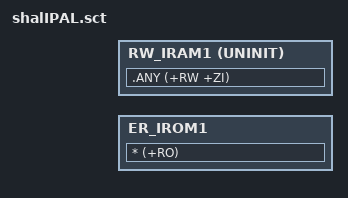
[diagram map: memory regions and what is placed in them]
#! armcc -E
#include "D:\##inhere\sdl\embedded\arm\embody\body\embenv\envcom\eEmemorymap.h"
; due to a bug in linker, you need to put the whole path ... thus change it by hand

; flash starts from SHALIPAL_ROMADDR and its size is SHALIPAL_ROMSIZE
LR_IROM1 EENV_MEMMAP_SHALIPAL_ROMADDR EENV_MEMMAP_SHALIPAL_ROMSIZE  {    ; load region size_region
  ER_IROM1 EENV_MEMMAP_SHALIPAL_ROMADDR EENV_MEMMAP_SHALIPAL_ROMSIZE  {  ; load address = execution address
	* (+RO)
  }
; ram starts from SHALIPAL_RAMADDR+SHALIPAL_RAMFOR_ZIDATA and its size is SHALIPAL_RAMFOR_RWDATA
  RW_IRAM1 (EENV_MEMMAP_SHALIPAL_RAMADDR+EENV_MEMMAP_SHALIPAL_RAMFOR_ZIDATA) UNINIT EENV_MEMMAP_SHALIPAL_RAMFOR_RWDATA  { 
   .ANY (+RW +ZI)
  }
}


;; flash starts from SHALIPAL_ROMADDR and its size is SHALIPAL_ROMSIZE
;LR_IROM1 0x08030000 0x00004000  {    ; load region size_region
;  ER_IROM1 0x08030000 0x00004000  {  ; load address = execution address
;	* (+RO)
;  }
;; ram starts from SHALIPAL_RAMADDR+SHALIPAL_RAMFOR_ZIDATA and its size is SHALIPAL_RAMFOR_RWDATA
;  RW_IRAM1 0x2000F008 UNINIT 0x0000000F8  { 
;   .ANY (+RW +ZI)
;  }
;}
